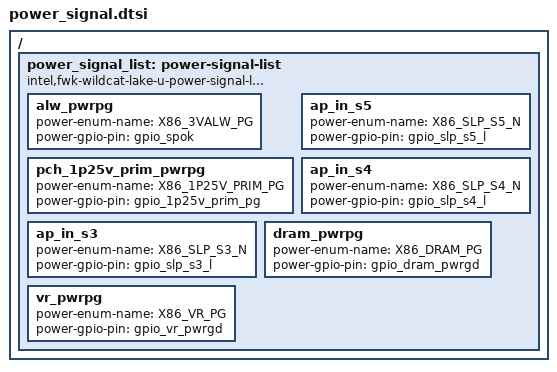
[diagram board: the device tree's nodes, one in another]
/* Copyright 2026 The ChromiumOS Authors
 * Use of this source code is governed by a BSD-style license that can be
 * found in the LICENSE file.
 */

/ {
	power_signal_list: power-signal-list {
		compatible = "intel,fwk-wildcat-lake-u-power-signal-list";

		alw_pwrpg {
			power-enum-name = "X86_3VALW_PG";
			power-gpio-pin = <&gpio_spok>;
		};
		pch_1p25v_prim_pwrpg {
			power-enum-name = "X86_1P25V_PRIM_PG";
			power-gpio-pin = <&gpio_1p25v_prim_pg>;
		};
		ap_in_s5 {
			power-enum-name = "X86_SLP_S5_N";
			power-gpio-pin = <&gpio_slp_s5_l>;
		};
		ap_in_s4 {
			power-enum-name = "X86_SLP_S4_N";
			power-gpio-pin = <&gpio_slp_s4_l>;
		};
		ap_in_s3 {
			power-enum-name = "X86_SLP_S3_N";
			power-gpio-pin = <&gpio_slp_s3_l>;
		};
		dram_pwrpg {
			power-enum-name = "X86_DRAM_PG";
			power-gpio-pin = <&gpio_dram_pwrgd>;
		};
		vr_pwrpg {
			power-enum-name = "X86_VR_PG";
			power-gpio-pin = <&gpio_vr_pwrgd>;
		};
	};
};
